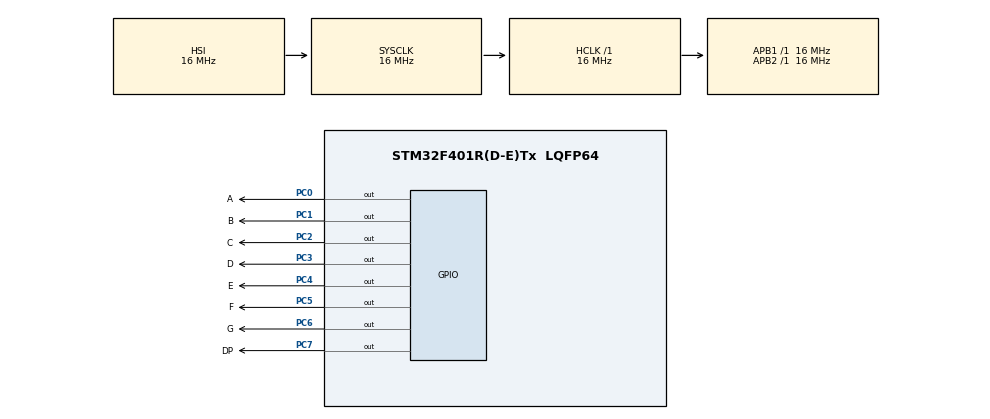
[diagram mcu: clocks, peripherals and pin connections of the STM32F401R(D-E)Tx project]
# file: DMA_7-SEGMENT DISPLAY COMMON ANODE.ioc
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Mcu.Family=STM32F4
PC7.GPIO_ModeDefaultOutputPP=GPIO_MODE_OUTPUT_OD
RCC.CortexFreq_Value=16000000
PC4.PinState=GPIO_PIN_SET
PC4.Signal=GPIO_Output
PC2.Signal=GPIO_Output
PC6.Signal=GPIO_Output
PC0.GPIO_Label=A
PC6.GPIO_Label=G
PC0.GPIO_ModeDefaultOutputPP=GPIO_MODE_OUTPUT_OD
Dma.TIM1_UP.0.Mode=DMA_CIRCULAR
PC2.GPIO_Speed=GPIO_SPEED_FREQ_LOW
PC0.Signal=GPIO_Output
PC3.GPIO_Speed=GPIO_SPEED_FREQ_LOW
ProjectManager.StackSize=0x400
PC3.PinState=GPIO_PIN_SET
PA13.Signal=SYS_JTMS-SWDIO
Dma.TIM1_UP.0.PeriphDataAlignment=DMA_PDATAALIGN_BYTE
Dma.TIM1_UP.0.MemInc=DMA_MINC_ENABLE
PC0.GPIO_Speed=GPIO_SPEED_FREQ_LOW
TIM1.Prescaler=999
ProjectManager.TargetToolchain=STM32CubeIDE
PC7.Signal=GPIO_Output
PC3.Signal=GPIO_Output
Dma.TIM1_UP.0.Priority=DMA_PRIORITY_LOW
PC1.PinState=GPIO_PIN_SET
RCC.LSE_VALUE=32768
RCC.AHBFreq_Value=16000000
PC6.PinState=GPIO_PIN_SET
RCC.HSE_VALUE=25000000
board=custom
PC7.GPIO_Speed=GPIO_SPEED_FREQ_LOW
RCC.VCOOutputFreq_Value=192000000
Dma.TIM1_UP.0.Instance=DMA2_Stream5
PC4.GPIO_Speed=GPIO_SPEED_FREQ_LOW
RCC.APB2Freq_Value=16000000
PC4.GPIO_Label=E
PA14.Mode=Serial_Wire
NVIC.DMA2_Stream5_IRQn=true\:0\:0\:false\:false\:true\:false\:true
PC1.GPIO_Label=B
PC7.PinState=GPIO_PIN_SET
PC1.GPIO_Speed=GPIO_SPEED_FREQ_LOW
PA13.Mode=Serial_Wire
Dma.TIM1_UP.0.PeriphInc=DMA_PINC_DISABLE
Mcu.Name=STM32F401R(D-E)Tx
VP_TIM1_VS_ClockSourceINT.Mode=Internal
PC7.GPIO_Label=DP
RCC.SYSCLKFreq_VALUE=16000000
Mcu.Package=LQFP64
PC2.PinState=GPIO_PIN_SET
PC5.PinState=GPIO_PIN_SET
Dma.TIM1_UP.0.Direction=DMA_MEMORY_TO_PERIPH
PC5.GPIO_Label=F
PA14.Signal=SYS_JTCK-SWCLK
ProjectManager.HeapSize=0x200
Dma.TIM1_UP.0.MemDataAlignment=DMA_MDATAALIGN_BYTE
RCC.HSI_VALUE=16000000
PC1.GPIO_ModeDefaultOutputPP=GPIO_MODE_OUTPUT_OD
NVIC.PriorityGroup=NVIC_PRIORITYGROUP_4
PC5.GPIO_Speed=GPIO_SPEED_FREQ_LOW
PC2.GPIO_ModeDefaultOutputPP=GPIO_MODE_OUTPUT_OD
PC3.GPIO_Label=D
PC5.Signal=GPIO_Output
TIM1.Period=31999
PC3.GPIO_ModeDefaultOutputPP=GPIO_MODE_OUTPUT_OD
PC4.GPIO_ModeDefaultOutputPP=GPIO_MODE_OUTPUT_OD
Dma.Request0=TIM1_UP
RCC.APB1Freq_Value=16000000
PC5.GPIO_ModeDefaultOutputPP=GPIO_MODE_OUTPUT_OD
PC6.GPIO_Speed=GPIO_SPEED_FREQ_LOW
PC2.GPIO_Label=C
PC0.PinState=GPIO_PIN_SET
PC1.Signal=GPIO_Output
PC6.GPIO_ModeDefaultOutputPP=GPIO_MODE_OUTPUT_OD
Dma.TIM1_UP.0.FIFOMode=DMA_FIFOMODE_DISABLE

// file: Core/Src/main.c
/* USER CODE BEGIN Header */
/**
 * This example shows
 * 	How to use DMA to show a number in a 7-segment display
 * 	Transfer data from memory to GPIOC with DMA
 * 	Transfer the data every timer request to change the number from 0  to 9
 *
 *
 *
 *NOTE:IN THIS CASE WE USE DMA2 BECAUSE IT HAS FULL ACCES TO AHB BUS MATRIX, WITH THIS
 *NOTE: WE CAN TRANSMIT FROM MEMORY TO GPIOC WITH TIMER1 UPDATED REQUEST(OVERFLOW)
  ******************************************************************************
  * @file           : main.c
  * @brief          : Main program body
  ******************************************************************************
  * @attention
  *
  * <h2><center>&copy; Copyright (c) 2021 STMicroelectronics.
  * All rights reserved.</center></h2>
  *
  * This software component is licensed by ST under BSD 3-Clause license,
  * the "License"; You may not use this file except in compliance with the
  * License. You may obtain a copy of the License at:
  *                        opensource.org/licenses/BSD-3-Clause
  *
  ******************************************************************************
  */
/* USER CODE END Header */
#include "main.h"
#include "dma.h"
#include "tim.h"
#include "gpio.h"

void SystemClock_Config(void);

int main(void)
{
  /* USER CODE BEGIN 1 */
	//The numbers variable stores the binary code  needed to show a number on the display
		//The Bitwise complement operator(~) is used to change the 1s to 0 because
		// we are using outputs with open-drain mode, so we need some outputs to be 0 to make the pattern
		// of a number. For example  0 =0011 1111 and after the ~ 0 = 1100 0000.
	const unsigned char numbers[10]={~0x3F,~0x06,~0x5B,~0x4F,~0x66,~0x6D,~0x7D,~0x07,~0x7F,~0x6F};
  /* USER CODE END 1 */

  /* MCU Configuration--------------------------------------------------------*/

  /* Reset of all peripherals, Initializes the Flash interface and the Systick. */
  HAL_Init();

  /* Configure the system clock */
  SystemClock_Config();

  /* Initialize all configured peripherals */
  MX_GPIO_Init();
  MX_DMA_Init();
  MX_TIM1_Init();
  //start the timer 1 to can generate a DMA request
  HAL_TIM_Base_Start(&htim1);
  //start the DMA to send data to GPIOC when a request is achivied
  HAL_DMA_Start(&hdma_tim1_up, (uint32_t)numbers, (uint32_t)&GPIOC->ODR, 10);
  //enbale TIMER 1 to generate the request to change the number
  __HAL_TIM_ENABLE_DMA(&htim1,TIM_DMA_UPDATE);

  /* Infinite loop */
  while (1)
  {

  }
}

void SystemClock_Config(void)
{
  RCC_OscInitTypeDef RCC_OscInitStruct = {0};
  RCC_ClkInitTypeDef RCC_ClkInitStruct = {0};

  /** Configure the main internal regulator output voltage
  */
  __HAL_RCC_PWR_CLK_ENABLE();
  __HAL_PWR_VOLTAGESCALING_CONFIG(PWR_REGULATOR_VOLTAGE_SCALE2);
  /** Initializes the RCC Oscillators according to the specified parameters
  * in the RCC_OscInitTypeDef structure.
  */
  RCC_OscInitStruct.OscillatorType = RCC_OSCILLATORTYPE_HSI;
  RCC_OscInitStruct.HSIState = RCC_HSI_ON;
  RCC_OscInitStruct.HSICalibrationValue = RCC_HSICALIBRATION_DEFAULT;
  RCC_OscInitStruct.PLL.PLLState = RCC_PLL_NONE;
  if (HAL_RCC_OscConfig(&RCC_OscInitStruct) != HAL_OK)
  {
    Error_Handler();
  }
  /** Initializes the CPU, AHB and APB buses clocks
  */
  RCC_ClkInitStruct.ClockType = RCC_CLOCKTYPE_HCLK|RCC_CLOCKTYPE_SYSCLK
                              |RCC_CLOCKTYPE_PCLK1|RCC_CLOCKTYPE_PCLK2;
  RCC_ClkInitStruct.SYSCLKSource = RCC_SYSCLKSOURCE_HSI;
  RCC_ClkInitStruct.AHBCLKDivider = RCC_SYSCLK_DIV1;
  RCC_ClkInitStruct.APB1CLKDivider = RCC_HCLK_DIV1;
  RCC_ClkInitStruct.APB2CLKDivider = RCC_HCLK_DIV1;

  if (HAL_RCC_ClockConfig(&RCC_ClkInitStruct, FLASH_LATENCY_0) != HAL_OK)
  {
    Error_Handler();
  }
}

void Error_Handler(void)
{
  __disable_irq();
  while (1)
  {
  }
}

/************************ (C) COPYRIGHT STMicroelectronics *****END OF FILE****/
